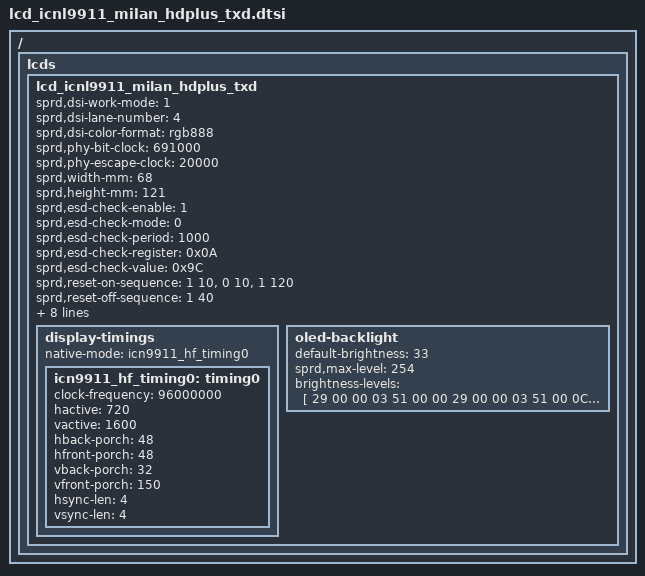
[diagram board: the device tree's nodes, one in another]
/ {
	fragment {
		target-path = "/";
		__overlay__ {
			lcds {
				lcd_icnl9911_milan_hdplus_txd: lcd_icnl9911_milan_hdplus_txd {

					sprd,dsi-work-mode = <1>;
					sprd,dsi-lane-number = <4>;
					sprd,dsi-color-format = "rgb888";

					sprd,phy-bit-clock = <691000>;
					sprd,phy-escape-clock = <20000>;

					sprd,width-mm = <68>;
					sprd,height-mm = <121>;

					sprd,esd-check-enable = <1>;
					sprd,esd-check-mode = <0>;  /*Read register*/
					sprd,esd-check-period = <1000>;
					sprd,esd-check-register = <0x0A>;
					sprd,esd-check-value = <0x9C>;

					sprd,reset-on-sequence = <1 10>, <0 10>, <1 120>;
					sprd,reset-off-sequence = <1 40>;

					sprd,initial-command = [
						39 00 00 03 F0 5A 59
						39 00 00 03 F1 A5 A6
			39 00 00 1F B0 87 86 05 04 8A 8B 04 05 55 55 55 55 1B 00 00 64 00 00 0F 05 04 03 02 01 02 03 04 00 00 00
			39 00 00 1E B1 53 42 85 00 1B 00 00 64 00 00 04 08 54 00 00 00 44 40 02 01 40 02 01 40 02 01 40 02 01
			39 00 00 12 B2 54 84 85 05 40 02 01 40 02 01 05 05 54 0C 0C 0D 0B
			39 00 00 20 B3 02 0E 0B 0E 0B 26 26 91 A2 33 44 00 26 00 18 01 02 08 20 30 08 09 44 20 40 20 40 08 09 22 33
			39 00 00 1D B4 02 02 00 00 E3 09 22 00 22 0D 0F 11 13 05 02 02 02 02 02 02 02 02 FF FF FC 00 00 00
			39 00 00 1D B5 00 00 00 00 E3 08 22 00 22 0C 0E 10 12 04 02 02 02 02 02 02 02 02 FF FF FC 00 00 00
			39 00 00 19 B8 00 00 00 00 00 00 00 00 00 00 00 00 00 00 00 00 00 00 00 00 00 00 00 00
			39 00 00 0E BB 01 05 09 11 0D 19 1D 55 25 69 00 21 25
			39 00 00 0F BC 00 00 00 00 02 20 FF 00 03 24 01 73 33 02
			39 00 00 0B BD E9 02 4F CF 72 A4 08 44 AE 15
			39 00 00 0B BE 73 87 64 3C 0C 77 43 07 0E 0E
			39 00 00 09 BF 07 25 07 25 7F 00 11 04
			39 00 00 0A C0 10 00 1F FF FF FF 00 FF 00
			39 00 00 14 C1 C0 20 20 96 04 30 30 04 2A 40 36 00 07 CF FF FF C0 00 C0
			23 00 00 02 C2 00
			39 00 00 0A C3 06 00 FF 00 FF 00 00 81 01
			39 00 00 0B C4 84 01 2B 41 00 3C 00 03 03 2E
			39 00 00 0C C5 03 1C C0 C0 40 10 42 44 0F 0F 14
			39 00 00 0B C6 87 96 2A 29 29 33 7F 34 08 04
			39 00 00 17 C7 FC C5 A2 88 58 38 06 57 1F F1 C4 91 EA BD A2 77 60 3C 1A 7F C0 00
			39 00 00 17 C8 FC C5 A2 88 58 38 06 57 1F F1 C4 91 EA BD A2 77 60 3C 1A 7F C0 00
			23 00 00 02 CB 00
			39 00 00 09 D0 80 0D FF 0F 61 0B 08 04
			23 00 00 02 D2 42
			39 00 00 05 FE FF FF FF 40
			39 00 00 1B E0 30 00 80 88 11 3F 22 62 DF A0 04 CC 01 FF F6 FF F0 FD FF FD F8 F5 FC FC FD FF
			39 00 00 18 E1 EF FE FE FE FE EE F0 20 33 FF 00 00 6A 90 C0 0D 6A F0 3E FF 00 06 40
			39 00 00 03 F1 5A 59
			39 00 00 03 F0 A5 A6
			39 00 00 03 51 ff ff
			23 00 00 02 53 2C
			23 00 00 02 55 00
			23 05 00 02 35 00
			23 78 00 02 11 00
			23 23 00 02 29 00
			23 05 00 02 26 01
						];
			sprd,page-unlock-command = [
			39 00 00 03 F0 5A 59  
			39 00 00 03 F1 A5 A6
						];
					sprd,sleep-in-command = [
			23 00 00 02 26 08
			23 23 00 02 28 00
			23 78 00 02 10 00
						];
					sprd,sleep-out-command = [
			23 78 00 02 11 00
			23 23 00 02 29 00
			23 00 00 02 26 01
						];

					display-timings {
						native-mode = <&icn9911_hf_timing0>;

						icn9911_hf_timing0: timing0 {
							clock-frequency = <96000000>;
				hactive = <720>;
				vactive = <1600>;
				hback-porch = <48>;
				hfront-porch = <48>;
				vback-porch = <32>;
				vfront-porch = <150>;
				hsync-len = <4>;
				vsync-len = <4>;
						};
					};
				oled-backlight {			
						default-brightness = <33>;	
						sprd,max-level = <254>;
						brightness-levels = [				
            		    	29 00 00 03 51 00 00
							29 00 00 03 51 00 0C
							29 00 00 03 51 00 14
							29 00 00 03 51 00 1C
							29 00 00 03 51 00 25
							29 00 00 03 51 00 2D
							29 00 00 03 51 00 35
							29 00 00 03 51 00 3D
							29 00 00 03 51 00 45
							29 00 00 03 51 00 4D
							29 00 00 03 51 00 55
							29 00 00 03 51 00 5D
							29 00 00 03 51 00 65
							29 00 00 03 51 00 6D
							29 00 00 03 51 00 75
							29 00 00 03 51 00 7D
							29 00 00 03 51 00 85
							29 00 00 03 51 00 8D
							29 00 00 03 51 00 95
							29 00 00 03 51 00 9D
							29 00 00 03 51 00 A5
							29 00 00 03 51 00 AD
							29 00 00 03 51 00 B5
							29 00 00 03 51 00 BD
							29 00 00 03 51 00 C5
							29 00 00 03 51 00 CD
							29 00 00 03 51 00 D5
							29 00 00 03 51 00 DD
							29 00 00 03 51 00 E5
							29 00 00 03 51 00 EE
							29 00 00 03 51 00 F6
							29 00 00 03 51 00 FE
							29 00 00 03 51 01 06
							29 00 00 03 51 01 0E
							29 00 00 03 51 01 16
							29 00 00 03 51 01 1E
							29 00 00 03 51 01 26
							29 00 00 03 51 01 2E
							29 00 00 03 51 01 36
							29 00 00 03 51 01 3E
							29 00 00 03 51 01 46
							29 00 00 03 51 01 4E
							29 00 00 03 51 01 56
							29 00 00 03 51 01 5E
							29 00 00 03 51 01 66
							29 00 00 03 51 01 6E
							29 00 00 03 51 01 76
							29 00 00 03 51 01 7E
							29 00 00 03 51 01 86
							29 00 00 03 51 01 8E
							29 00 00 03 51 01 96
							29 00 00 03 51 01 9E
							29 00 00 03 51 01 A6
							29 00 00 03 51 01 AE
							29 00 00 03 51 01 B7
							29 00 00 03 51 01 BF
							29 00 00 03 51 01 C7
							29 00 00 03 51 01 CF
							29 00 00 03 51 01 D7
							29 00 00 03 51 01 DF
							29 00 00 03 51 01 E7
							29 00 00 03 51 01 EF
							29 00 00 03 51 01 F7
							29 00 00 03 51 01 FF
							29 00 00 03 51 02 07
							29 00 00 03 51 02 0F
							29 00 00 03 51 02 17
							29 00 00 03 51 02 1F
							29 00 00 03 51 02 27
							29 00 00 03 51 02 2F
							29 00 00 03 51 02 37
							29 00 00 03 51 02 3F
							29 00 00 03 51 02 47
							29 00 00 03 51 02 4F
							29 00 00 03 51 02 57
							29 00 00 03 51 02 5F
							29 00 00 03 51 02 67
							29 00 00 03 51 02 6F
							29 00 00 03 51 02 77
							29 00 00 03 51 02 80
							29 00 00 03 51 02 88
							29 00 00 03 51 02 90
							29 00 00 03 51 02 98
							29 00 00 03 51 02 A0
							29 00 00 03 51 02 A8
							29 00 00 03 51 02 B0
							29 00 00 03 51 02 B8
							29 00 00 03 51 02 C0
							29 00 00 03 51 02 C8
							29 00 00 03 51 02 D0
							29 00 00 03 51 02 D8
							29 00 00 03 51 02 E0
							29 00 00 03 51 02 E8
							29 00 00 03 51 02 F0
							29 00 00 03 51 02 F8
							29 00 00 03 51 03 00
							29 00 00 03 51 03 08
							29 00 00 03 51 03 10
							29 00 00 03 51 03 18
							29 00 00 03 51 03 20
							29 00 00 03 51 03 28
							29 00 00 03 51 03 30
							29 00 00 03 51 03 38
							29 00 00 03 51 03 40
							29 00 00 03 51 03 49
							29 00 00 03 51 03 51
							29 00 00 03 51 03 59
							29 00 00 03 51 03 61
							29 00 00 03 51 03 69
							29 00 00 03 51 03 71
							29 00 00 03 51 03 79
							29 00 00 03 51 03 81
							29 00 00 03 51 03 89
							29 00 00 03 51 03 91
							29 00 00 03 51 03 99
							29 00 00 03 51 03 A1
							29 00 00 03 51 03 A9
							29 00 00 03 51 03 B1
							29 00 00 03 51 03 B9
							29 00 00 03 51 03 C1
							29 00 00 03 51 03 C9
							29 00 00 03 51 03 D1
							29 00 00 03 51 03 D9
							29 00 00 03 51 03 E1
							29 00 00 03 51 03 E9
							29 00 00 03 51 03 F1
							29 00 00 03 51 03 F9
							29 00 00 03 51 04 01
							29 00 00 03 51 04 09
							29 00 00 03 51 04 12
							29 00 00 03 51 04 1A
							29 00 00 03 51 04 22
							29 00 00 03 51 04 2A
							29 00 00 03 51 04 32
							29 00 00 03 51 04 3A
							29 00 00 03 51 04 42
							29 00 00 03 51 04 4A
							29 00 00 03 51 04 52
							29 00 00 03 51 04 5A
							29 00 00 03 51 04 62
							29 00 00 03 51 04 6A
							29 00 00 03 51 04 72
							29 00 00 03 51 04 7A
							29 00 00 03 51 04 82
							29 00 00 03 51 04 8A
							29 00 00 03 51 04 92
							29 00 00 03 51 04 9A
							29 00 00 03 51 04 A2
							29 00 00 03 51 04 AA
							29 00 00 03 51 04 B2
							29 00 00 03 51 04 BA
							29 00 00 03 51 04 C2
							29 00 00 03 51 04 CA
							29 00 00 03 51 04 D2
							29 00 00 03 51 04 DB
							29 00 00 03 51 04 E3
							29 00 00 03 51 04 EB
							29 00 00 03 51 04 F3
							29 00 00 03 51 04 FB
							29 00 00 03 51 05 03
							29 00 00 03 51 05 0B
							29 00 00 03 51 05 13
							29 00 00 03 51 05 1B
							29 00 00 03 51 05 23
							29 00 00 03 51 05 2B
							29 00 00 03 51 05 33
							29 00 00 03 51 05 3B
							29 00 00 03 51 05 43
							29 00 00 03 51 05 4B
							29 00 00 03 51 05 53
							29 00 00 03 51 05 5B
							29 00 00 03 51 05 63
							29 00 00 03 51 05 6B
							29 00 00 03 51 05 73
							29 00 00 03 51 05 7B
							29 00 00 03 51 05 83
							29 00 00 03 51 05 8B
							29 00 00 03 51 05 93
							29 00 00 03 51 05 9B
							29 00 00 03 51 05 A4
							29 00 00 03 51 05 AC
							29 00 00 03 51 05 B4
							29 00 00 03 51 05 BC
							29 00 00 03 51 05 C4
							29 00 00 03 51 05 CC
							29 00 00 03 51 05 D4
							29 00 00 03 51 05 DC
							29 00 00 03 51 05 E4
							29 00 00 03 51 05 EC
							29 00 00 03 51 05 F4
							29 00 00 03 51 05 FC
							29 00 00 03 51 06 04
							29 00 00 03 51 06 0C
							29 00 00 03 51 06 14
							29 00 00 03 51 06 1C
							29 00 00 03 51 06 24
							29 00 00 03 51 06 2C
							29 00 00 03 51 06 34
							29 00 00 03 51 06 3C
							29 00 00 03 51 06 44
							29 00 00 03 51 06 4C
							29 00 00 03 51 06 54
							29 00 00 03 51 06 5C
							29 00 00 03 51 06 64
							29 00 00 03 51 06 6D
							29 00 00 03 51 06 75
							29 00 00 03 51 06 7D
							29 00 00 03 51 06 85
							29 00 00 03 51 06 8D
							29 00 00 03 51 06 95
							29 00 00 03 51 06 9D
							29 00 00 03 51 06 A5
							29 00 00 03 51 06 AD
							29 00 00 03 51 06 B5
							29 00 00 03 51 06 BD
							29 00 00 03 51 06 C5
							29 00 00 03 51 06 CD
							29 00 00 03 51 06 D5
							29 00 00 03 51 06 DD
							29 00 00 03 51 06 E5
							29 00 00 03 51 06 ED
							29 00 00 03 51 06 F5
							29 00 00 03 51 06 FD
							29 00 00 03 51 07 05
							29 00 00 03 51 07 0D
							29 00 00 03 51 07 15
							29 00 00 03 51 07 1D
							29 00 00 03 51 07 25
							29 00 00 03 51 07 2D
							29 00 00 03 51 07 36
							29 00 00 03 51 07 3E
							29 00 00 03 51 07 46
							29 00 00 03 51 07 4E
							29 00 00 03 51 07 56
							29 00 00 03 51 07 5E
							29 00 00 03 51 07 66
							29 00 00 03 51 07 6E
							29 00 00 03 51 07 76
							29 00 00 03 51 07 7E
							29 00 00 03 51 07 86
							29 00 00 03 51 07 8E
							29 00 00 03 51 07 96
							29 00 00 03 51 07 9E
							29 00 00 03 51 07 A6
							29 00 00 03 51 07 AE
							29 00 00 03 51 07 B6
							29 00 00 03 51 07 BE
							29 00 00 03 51 07 C6
							29 00 00 03 51 07 CE
							29 00 00 03 51 07 D6
							29 00 00 03 51 07 DE
							29 00 00 03 51 07 E6
							29 00 00 03 51 07 EE
							29 00 00 03 51 07 F6
							29 00 00 03 51 07 FF
						];
					};
					
				};
			};
		};
	};
};

